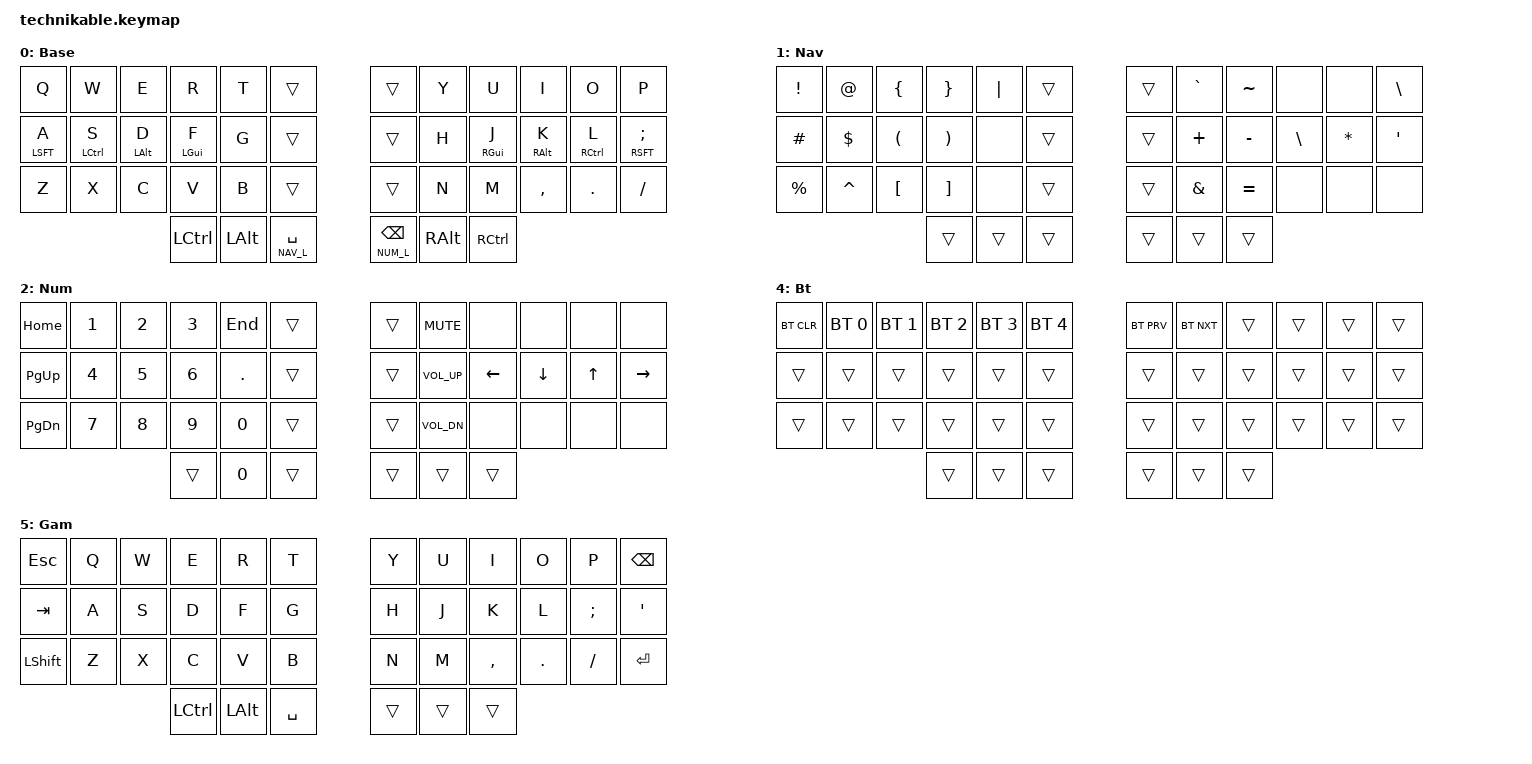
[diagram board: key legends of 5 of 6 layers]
/*
 * Copyright (c) 2022 Pete Johanson
 *
 * SPDX-License-Identifier: MIT
 */

#include <behaviors.dtsi>
#include <dt-bindings/zmk/keys.h>
#include <dt-bindings/zmk/bt.h>
#include <dt-bindings/zmk/outputs.h>

#define BAS_L 0
#define NAV_L 1
#define NUM_L 2
#define SYM_L 3
#define BT_L  4
#define GAM_L 5

&mt {
    flavor = "tap-preferred";
    tapping_term_ms = <200>;
    quick_tap_ms = <0>;
};

// Using layer taps on thumbs, having quick tap as well helps w/ repeating space/backspace
&lt { 
    quick_tap_ms = <200>; 
    };

/ { 

    combos {
        compatible = "zmk,combos";
        combo_esc {
            timeout-ms = <50>;
            key-positions = <0 1>;
            bindings = <&kp ESC>;
        };
        
            combo_bspc {
            timeout-ms = <50>;
            key-positions = <13 14>;
            bindings = <&kp BSPC>;
        };
        
            combo_leftent {
            timeout-ms = <50>;
            key-positions = <13 15>;
            bindings = <&kp ENTER>;
        };
        
            combo_rightent {
            timeout-ms = <50>;
            key-positions = <21 22>;
            bindings = <&kp ENTER>;
        };
        
       
            combo_del {
            timeout-ms = <50>;
            key-positions = <7 8>;
            bindings = <&kp DEL>;
        };
                
        
            combo_undsc {
            timeout-ms = <50>;
            key-positions = <25 26>;
            bindings = <&kp MINUS>;
        };
        
        
            combo_less {
            timeout-ms = <50>;
            key-positions = <19 20>;
            bindings = <&kp LT>;
        };

                
            combo_more {
            timeout-ms = <50>;
            key-positions = <20 21>;
            bindings = <&kp GT>;
        };
        
        
            combo_quote {
            timeout-ms = <50>;
            key-positions = <32 33>;
            bindings = <&kp SQT>;
        };


            combo_minus {
            timeout-ms = <50>;
            key-positions = <33 34>;
            bindings = <&kp UNDER>;
        };


            combo_tab {
            timeout-ms = <50>;
            key-positions = <13 25>;
            bindings = <&kp TAB>;
        };
        
            combo_bt {
            timeout-ms = <50>;
            key-positions = <34 35>;
            bindings = <&mo 4>;
        };
        
         combo_bootloader {
            timeout-ms = <50>;
            key-positions = <0 11>;
            bindings = <&bootloader>;
        };

	   combo_workspaceleft {
	   timeout-ms = <50>;
	   key-positions = <1 13>;
	   bindings = <&kp RG(RC(LEFT))>;
	};
	
	  combo_workspaceright {
	  timeout-ms = <50>;
	  key-positions = <3 15>;
	  bindings = <&kp RG(RC(RIGHT))>;
	};
	
	 combo_alttab {
	  timeout-ms = <20>;
	  key-positions = <2 14>;
	  bindings = <&kp LA(TAB)>;
	};

	combo_newtab {
            timeout-ms = <50>;
            key-positions = <14 15>;
            bindings = <&kp TAB>;
        };

    combo_game {
            timeout-ms = <50>;
            key-positions = <5 6 17 18>;
            bindings = <&tog 5>;
        };
        
    };
};

#define QWERTY_BASE 1

// #define TBLE_ORTHO   true
// #define TBLE_MIT     true
#define TBLE_DUAL_2U true

#define BT(n) BT_SEL n

/ {
    chosen {
       zmk,matrix_transform =
#ifdef TBLE_DUAL_2U
                       &dual_2u_transform;
#elif defined(TBLE_MIT)
                       &mit_transform;
#else
                       &ortho_transform;
#endif
    };

    conditional_layers {
        compatible = "zmk,conditional-layers";
	tri_layer {
	    if-layers = <NAV_L NUM_L>;
	    then-layer = <SYM_L>;
	};
    };

    keymap {
        compatible = "zmk,keymap";

        base_layer {
            label = "Base";
            bindings = <
#ifdef QWERTY_BASE
&kp Q      &kp W      &kp E       &kp R          &kp T          &trans          &trans         &kp Y            &kp U          &kp I       &kp O      &kp P
&mt LSFT A      &mt LCTL S      &mt LALT D       &mt LGUI F          &kp G          &trans          &trans         &kp H            &mt RGUI J          &mt RALT K       &mt RCTL L      &mt RSFT SEMI
&kp Z      &kp X      &kp C       &kp V          &kp B          &trans          &trans         &kp N            &kp M          &kp COMMA   &kp DOT    &kp FSLH 
#else
&kp Q      &kp W      &kp E       &kp R          &kp T          &trans          &trans         &kp Y            &kp U          &kp I       &kp O      &kp P
&mt LSFT A      &mt LCTL S      &mt LALT D       &mt LGUI F          &kp G          &trans          &trans         &kp H            &mt RGUI J          &mt RALT K       &mt RCTL L      &mt RSFT SEMI
&kp Z      &kp X      &kp C       &kp V          &kp B          &trans          &trans         &kp N            &kp M          &kp COMMA   &kp DOT    &kp FSLH
#endif
#ifdef TBLE_DUAL_2U
                       &kp LCTRL  &kp LALT      &lt NAV_L SPACE                &lt NUM_L BSPC              &kp RALT    &kp RCTRL
#elif defined(TBLE_MIT)
                       &kp LCTRL  &kp LALT    &mo NAV_L          &kp SPACE                   &mo NUM_L      &kp RALT    &kp RCTRL
#else
                       &kp LCTRL  &kp LALT    &mo NAV_L      &kp SPACE      &kp SPACE        &mo NUM_L      &kp RALT    &kp RCTRL
#endif
            >;
        };

        nav_layer {
            label = "Nav";
            bindings = <
&kp EXCL    &kp AT      &kp LBRC     &kp RBRC  &kp PIPE  &trans &trans  	&kp GRAVE   &kp TILDE   &none       &none       &kp BSLH
&kp HASH    &kp DLLR    &kp LPAR     &kp RPAR  &none 	 &trans &trans	    &kp PLUS    &kp MINUS   &kp BSLH    &kp STAR    &kp SQT 
&kp PRCNT   &kp CARET   &kp LBKT     &kp RBKT  &none 	 &trans &trans	    &kp AMPS    &kp EQUAL   &none       &none       &none    
#ifdef TBLE_DUAL_2U
                      &trans     &trans              &trans                    &trans       &trans         &trans
#elif defined(TBLE_MIT)
                      &trans     &trans      &trans                &trans             &trans      &trans   &trans
#else
                      &trans     &trans      &trans          &trans       &trans    &trans  &trans         &trans
#endif
            >;
        };

        num_layer {
            label = "Num";
            bindings = <
&kp HOME    &kp N1  &kp N2  &kp N3   &kp END  &trans &trans  		&kp C_MUTE  &none &none &none &none 
&kp PG_UP   &kp N4  &kp N5  &kp N6   &kp DOT  &trans &trans 		&kp C_VOL_UP &kp LEFT  &kp DOWN  &kp UP   &kp RIGHT
&kp PG_DN   &kp N7  &kp N8  &kp N9   &kp N0   &trans &trans 		&kp C_VOL_DN &none &none &none  &none
#ifdef TBLE_DUAL_2U
                     &trans     &kp N0              &trans                 &trans            &trans         &trans
#elif defined(TBLE_MIT)
                     &trans     &kp N0      &trans           &none            &kp ESC        &kp DEL      &trans
#else
                     &trans     &kp N0      &trans    &none         &none     &kp ESC        &kp DEL      &trans
#endif
            >;
        };

        sym_layer {
            label = "Sym";
            bindings = <
&bt BT_SEL 0  &bt BT_SEL 1 &bt BT_SEL 2  &bt BT_SEL 3  &bt BT_SEL 4  &none  &none  &none  &none   &none   &none &bt BT_CLR
&trans &none  &none  &none  &none  &none  &none  &none  &none  &none   &none   &none
&trans &none  &none  &none  &none  &none  &none  &none  &none  &none   &none   &none
&trans &trans &trans &trans &trans &bootloader &none &trans &trans &trans &trans &trans
#ifdef TBLE_DUAL_2U
                      &trans     &trans      &trans          &trans       &trans      &trans
#elif defined(TBLE_MIT)
                      &trans     &trans      &trans          &trans       &trans      &trans    &trans
#else
                      &trans     &trans      &trans          &trans       &trans      &trans    &trans  &none
#endif
            >;
        };

                flock_layer {
            label = "Bt";
            bindings = <
&bt BT_CLR   &bt BT_SEL 0 &bt BT_SEL 1 &bt BT_SEL 2 &bt BT_SEL 3 &bt BT_SEL 4 &bt BT_PRV &bt BT_NXT &trans &trans  &trans  &trans
&trans       &trans       &trans       &trans       &trans       &trans       &trans     &trans     &trans     &trans  &trans  &trans
&trans       &trans       &trans       &trans       &trans       &trans       &trans     &trans     &trans     &trans  &trans  &trans
#ifdef TBLE_DUAL_2U
                     &trans     &trans              &trans                 &trans            &trans         &trans
#elif defined(TBLE_MIT)
                     &trans     &trans      &trans           &none            &trans        &trans      &trans
#else
                     &trans     &trans     &trans    &none         &none     &trans        &trans      &trans
#endif
            >;
        };

gam_layer {
            label = "Gam";
            bindings = <
&kp ESC    &kp Q      &kp W      &kp E       &kp R          &kp T          &kp Y            &kp U          &kp I       &kp O      &kp P         &kp BKSP
 &kp TAB    &kp A      &kp S      &kp D       &kp F          &kp G          &kp H            &kp J          &kp K       &kp L      &kp SEMI      &kp QUOT
 &kp LSHFT  &kp Z      &kp X      &kp C       &kp V          &kp B          &kp N            &kp M          &kp COMMA   &kp DOT    &kp FSLH      &kp RET
#ifdef TBLE_DUAL_2U
                      &kp LCTL     &kp LALT      &kp SPC          &trans       &trans      &trans
#elif defined(TBLE_MIT)
                      &trans     &trans      &trans          &trans       &trans      &trans    &trans
#else
                      &trans     &trans      &trans          &trans       &trans      &trans    &trans  &none
#endif
            >;
        };

    };
};

